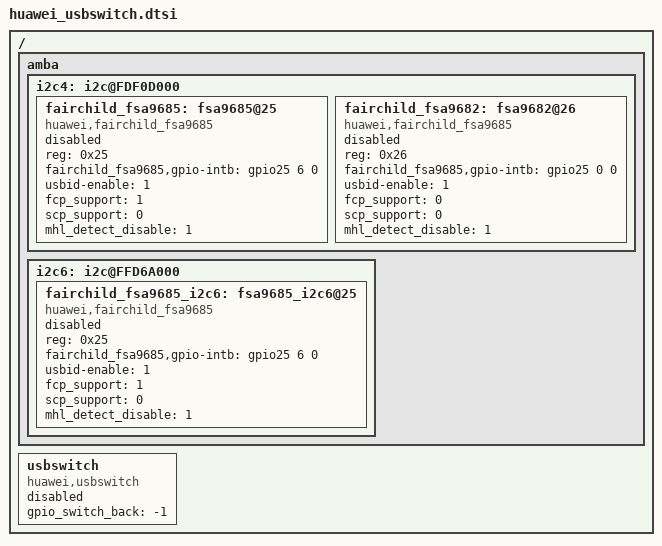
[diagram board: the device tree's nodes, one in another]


/{
	amba{
		i2c4: i2c@FDF0D000 {
			fairchild_fsa9685: fsa9685@25 {
				compatible = "huawei,fairchild_fsa9685";
				reg = <0x25>;
				fairchild_fsa9685,gpio-intb = <&gpio25 6 0>;
				usbid-enable = <1>;
				fcp_support = <1>;
				scp_support = <0>;
				mhl_detect_disable = <1>;
				status = "disabled";
			};
			fairchild_fsa9682: fsa9682@26 {
				compatible = "huawei,fairchild_fsa9685";
				reg = <0x26>;
				fairchild_fsa9685,gpio-intb = <&gpio25 0 0>;
				usbid-enable = <1>;
				fcp_support = <0>;
				scp_support = <0>;
				mhl_detect_disable = <1>;
				status = "disabled";
			};
		};
		i2c6: i2c@FFD6A000 {
			fairchild_fsa9685_i2c6: fsa9685_i2c6@25 {
				compatible = "huawei,fairchild_fsa9685";
				reg = <0x25>;
				fairchild_fsa9685,gpio-intb = <&gpio25 6 0>;
				usbid-enable = <1>;
				fcp_support = <1>;
				scp_support = <0>;
				mhl_detect_disable = <1>;
				status = "disabled";
                       };
               };
	};

	usbswitch: usbswitch {
		compatible = "huawei,usbswitch";
		gpio_switch_back = "-1";
		status = "disabled";
	};
};
